# haltium_sysctrl register map
Vendor: Nordic Semiconductor; Series: nRFHaltium; File version: 1
Registers are 32-bit, read-write, reset 0x0 unless marked. A register's access mark holds for its fields unless they carry their own. Offsets are from the block's base; [hi:lo] are bit positions; lines under a group give offsets from that group; {n}, {i} and the like mark numbered series.

## GPPIB0_S — PPIB APB registers 0
Base 0x5F098000
Same registers: GPPIB1_S 0x5F8EF000, GPPIB2_S 0x5F925000, GPPIB3_S 0x5F926000, GPPIB4_S 0x5F98D000, GPPIB5_S 0x5F99D000, GPPIB6_S 0x5F9AD000, GPPIB7_S 0x5F9BD000, GPPIB8_S 0x5F9CD000, GPPIB9_S 0x5F9DD000
{0x0+4i} TASKS_SEND[{i}] (i=0..15) wo — Description collection: This task is unused, but the PPIB provides the SUBSCRIBE task to connect SEND [n] task.
  [0] TASKS_SEND — This task is unused, but the PPIB provides the SUBSCRIBE task to connect SEND [n] task.
    1=Trigger task
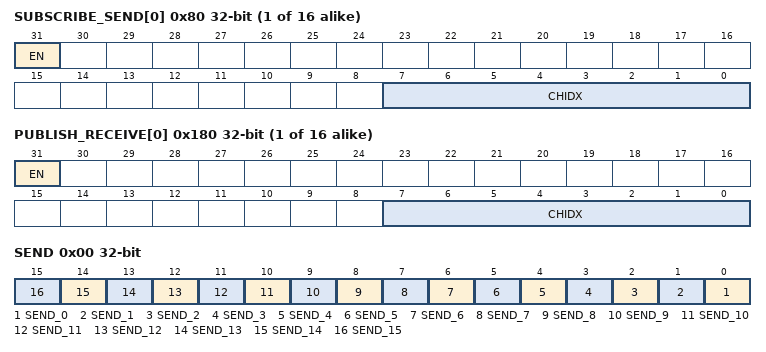
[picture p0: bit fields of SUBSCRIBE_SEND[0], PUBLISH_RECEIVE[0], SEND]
{0x80+4i} SUBSCRIBE_SEND[{i}] (i=0..15) — Description collection: Subscribe configuration for task SEND[n]
  [31] EN
    0=Disabled (Disable subscription); 1=Enabled (Enable subscription)
  [7:0] CHIDX — DPPI channel that task SEND[n] will subscribe to
{0x100+4i} EVENTS_RECEIVE[{i}] (i=0..15) — Description collection: This event is unused, but the PPIB provides the PUBLISH event to connect RECEIVE [n] event.
  [0] EVENTS_RECEIVE — This event is unused, but the PPIB provides the PUBLISH event to connect RECEIVE [n] event.
    0=NotGenerated (Event not generated); 1=Generated (Event generated)
{0x180+4i} PUBLISH_RECEIVE[{i}] (i=0..15) — Description collection: Publish configuration for event RECEIVE[n]
  [31] EN
    0=Disabled (Disable publishing); 1=Enabled (Enable publishing)
  [7:0] CHIDX — DPPI channel that event RECEIVE[n] will publish to
0x400 OVERFLOW group — Unspecified
  0x00 SEND — The task overflow for SEND tasks using SUBSCRIBE_SEND. Write 0 to clear.
    [all] fields
      1=Overflow (Task overflow is happened.); 0=NoOverflow (Task overflow is not happened.)
    [n] SEND_{n} (n=0..15) — The status for tasks overflow at SUBSCRIBE_SEND[{n}].

## GAMBIX0_S — AMBA interconnect 0
Base 0x5F8C2000
Same registers: GAMBIX1_S 0x5F902000
0x400 PRIORITY group — Unspecified
  {0x0+4j} MASTER[{j}] (j=0..15) — Description collection: AMBIX bus master priority register
    [1:0] PRIORITY — Priority register for the master
      {v}=Pri{v} (Priority {v}) (v=0..3)

## GMEMCONF0_S — Memory configuration 0
Base 0x5F8C7000
Same registers: GMEMCONF1_S 0x5F905000
{0x500+0x10*i} POWER[{i}] (i=0..3) group — Unspecified
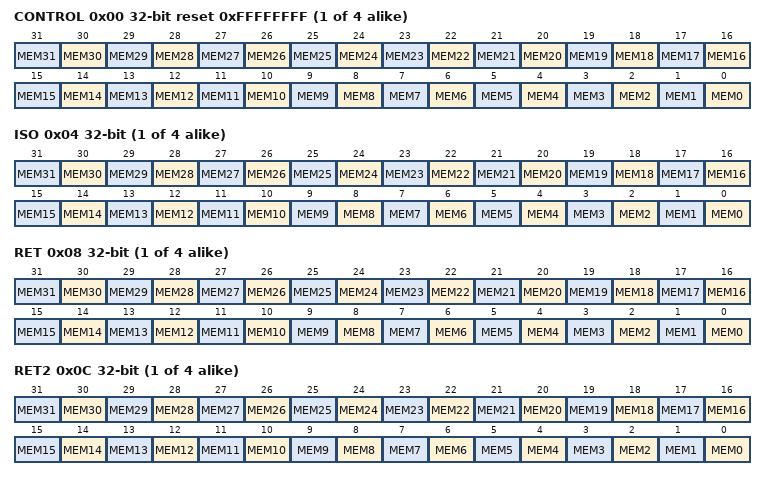
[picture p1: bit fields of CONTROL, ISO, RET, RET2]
  0x00 CONTROL reset 0xFFFFFFFF — Description cluster: RAM/ROM[n] power control register.
    [all] fields
      0=Off (Power down); 1=On (Power up)
    [n] MEM{n} (n=0..31) — Keep the RAM/ROM block MEM[{n}] on or off when in System ON mode.
  0x04 ISO — Description cluster: RAM/ROM [n] power isolation control register.
    [all] fields
      0=Off (Isolation off); 1=On (Isolation on)
    [n] MEM{n} (n=0..31) — Turn on/off the power isolation for RAM/ROM block MEM[{n}].
  0x08 RET — Description cluster: RAM retention for RAM/ROM [n].
    [all] fields
      0=Off (Retention off); 1=On (Retention on)
    [n] MEM{n} (n=0..31) — Keep the RAM block MEM[{n}] retained when in System OFF mode.
  0x0C RET2 — Description cluster: RAM retention for the second bank in the RAM block
    [all] fields
      0=Off (Retention off); 1=On (Retention on)
    [n] MEM{n} (n=0..31) — Keep the second bank in RAM block MEM[{n}] retained when in System OFF mode.
{0x600+0x18*i} REPAIR[{i}] (i=0..31) group — Unspecified
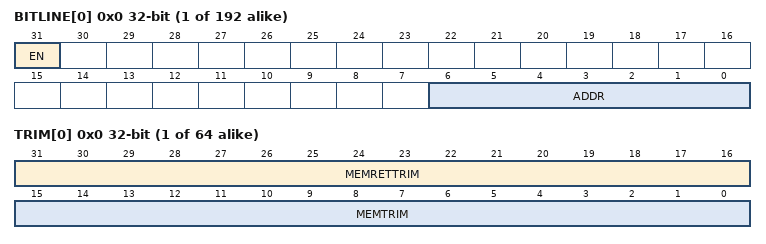
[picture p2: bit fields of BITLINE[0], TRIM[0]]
  {0x0+4j} BITLINE[{j}] (j=0..5) — Description collection: RAM repair bitline configuration RAM/ROM blocks.
    [31] EN — Enable bitline repair
      0=Disabled (Repair disabled.); 1=Enabled (Repair enabled.)
    [6:0] ADDR — Repair address of the bitline
0x900 BLOCKTYPE group — Unspecified
  {0x0+4j} TRIM[{j}] (j=0..63) — Description collection: Trim configuration for the RAM/ROM block types.
    [31:16] MEMRETTRIM — Trimming for retention mode for decreased leakage. Must be kept active in RAM retention mode.
    [15:0] MEMTRIM — Read/write margin trim.
